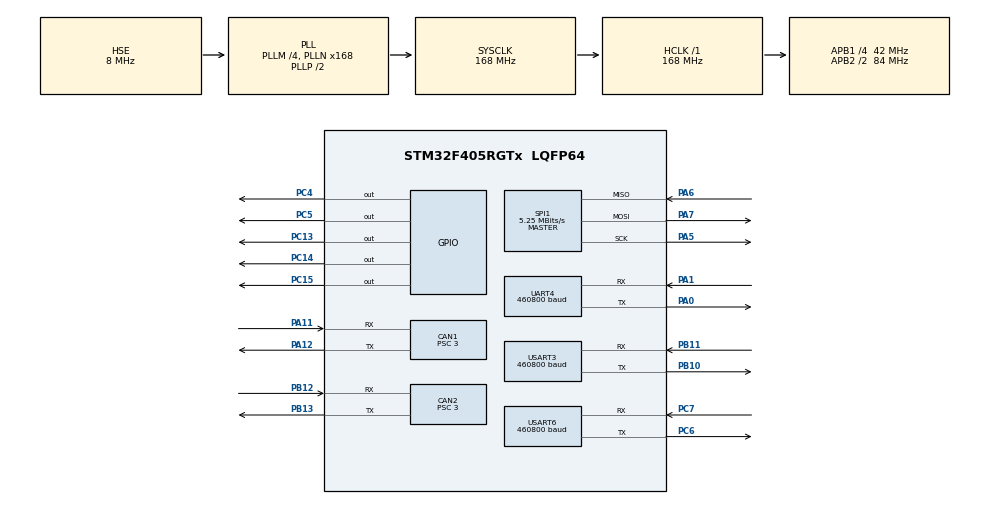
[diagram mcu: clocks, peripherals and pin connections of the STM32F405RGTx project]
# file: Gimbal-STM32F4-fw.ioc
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CAN1.BS1=CAN_BS1_9TQ
CAN1.BS2=CAN_BS2_4TQ
CAN1.CalculateBaudRate=1000000
CAN1.CalculateTimeBit=1000
CAN1.CalculateTimeQuantum=71.42857142857143
CAN1.Prescaler=3
CAN2.BS1=CAN_BS1_9TQ
CAN2.BS2=CAN_BS2_4TQ
CAN2.CalculateBaudRate=1000000
CAN2.CalculateTimeBit=1000
CAN2.CalculateTimeQuantum=71.42857142857143
CAN2.Prescaler=3
Dma.Request0=USART3_RX
Dma.Request1=USART3_TX
Dma.Request2=UART4_RX
Dma.Request3=UART4_TX
Dma.Request4=USART6_RX
Dma.Request5=USART6_TX
Dma.UART4_RX.2.Direction=DMA_PERIPH_TO_MEMORY
Dma.UART4_RX.2.FIFOMode=DMA_FIFOMODE_DISABLE
Dma.UART4_RX.2.Instance=DMA1_Stream2
Dma.UART4_RX.2.MemDataAlignment=DMA_MDATAALIGN_BYTE
Dma.UART4_RX.2.MemInc=DMA_MINC_ENABLE
Dma.UART4_RX.2.Mode=DMA_CIRCULAR
Dma.UART4_RX.2.PeriphDataAlignment=DMA_PDATAALIGN_BYTE
Dma.UART4_RX.2.PeriphInc=DMA_PINC_DISABLE
Dma.UART4_RX.2.Priority=DMA_PRIORITY_LOW
Dma.UART4_TX.3.Direction=DMA_MEMORY_TO_PERIPH
Dma.UART4_TX.3.FIFOMode=DMA_FIFOMODE_DISABLE
Dma.UART4_TX.3.Instance=DMA1_Stream4
Dma.UART4_TX.3.MemDataAlignment=DMA_MDATAALIGN_BYTE
Dma.UART4_TX.3.MemInc=DMA_MINC_ENABLE
Dma.UART4_TX.3.Mode=DMA_NORMAL
Dma.UART4_TX.3.PeriphDataAlignment=DMA_PDATAALIGN_BYTE
Dma.UART4_TX.3.PeriphInc=DMA_PINC_DISABLE
Dma.UART4_TX.3.Priority=DMA_PRIORITY_LOW
Dma.USART3_RX.0.Direction=DMA_PERIPH_TO_MEMORY
Dma.USART3_RX.0.FIFOMode=DMA_FIFOMODE_DISABLE
Dma.USART3_RX.0.Instance=DMA1_Stream1
Dma.USART3_RX.0.MemDataAlignment=DMA_MDATAALIGN_BYTE
Dma.USART3_RX.0.MemInc=DMA_MINC_ENABLE
Dma.USART3_RX.0.Mode=DMA_NORMAL
Dma.USART3_RX.0.PeriphDataAlignment=DMA_PDATAALIGN_BYTE
Dma.USART3_RX.0.PeriphInc=DMA_PINC_DISABLE
Dma.USART3_RX.0.Priority=DMA_PRIORITY_VERY_HIGH
Dma.USART3_TX.1.Direction=DMA_MEMORY_TO_PERIPH
Dma.USART3_TX.1.FIFOMode=DMA_FIFOMODE_DISABLE
Dma.USART3_TX.1.Instance=DMA1_Stream3
Dma.USART3_TX.1.MemDataAlignment=DMA_MDATAALIGN_BYTE
Dma.USART3_TX.1.MemInc=DMA_MINC_ENABLE
Dma.USART3_TX.1.Mode=DMA_NORMAL
Dma.USART3_TX.1.PeriphDataAlignment=DMA_PDATAALIGN_BYTE
Dma.USART3_TX.1.PeriphInc=DMA_PINC_DISABLE
Dma.USART3_TX.1.Priority=DMA_PRIORITY_VERY_HIGH
Dma.USART6_RX.4.Direction=DMA_PERIPH_TO_MEMORY
Dma.USART6_RX.4.FIFOMode=DMA_FIFOMODE_DISABLE
Dma.USART6_RX.4.Instance=DMA2_Stream1
Dma.USART6_RX.4.MemDataAlignment=DMA_MDATAALIGN_BYTE
Dma.USART6_RX.4.MemInc=DMA_MINC_ENABLE
Dma.USART6_RX.4.Mode=DMA_CIRCULAR
Dma.USART6_RX.4.PeriphDataAlignment=DMA_PDATAALIGN_BYTE
Dma.USART6_RX.4.PeriphInc=DMA_PINC_DISABLE
Dma.USART6_RX.4.Priority=DMA_PRIORITY_LOW
Dma.USART6_TX.5.Direction=DMA_MEMORY_TO_PERIPH
Dma.USART6_TX.5.FIFOMode=DMA_FIFOMODE_DISABLE
Dma.USART6_TX.5.Instance=DMA2_Stream6
Dma.USART6_TX.5.MemDataAlignment=DMA_MDATAALIGN_BYTE
Dma.USART6_TX.5.MemInc=DMA_MINC_ENABLE
Dma.USART6_TX.5.Mode=DMA_NORMAL
Dma.USART6_TX.5.PeriphDataAlignment=DMA_PDATAALIGN_BYTE
Dma.USART6_TX.5.PeriphInc=DMA_PINC_DISABLE
Dma.USART6_TX.5.Priority=DMA_PRIORITY_LOW
Mcu.Family=STM32F4
Mcu.Name=STM32F405RGTx
Mcu.Package=LQFP64
NVIC.CAN1_RX0_IRQn=true\:0\:0\:false\:false\:true\:true\:true\:true
NVIC.CAN2_RX0_IRQn=true\:0\:0\:false\:false\:true\:true\:true\:true
NVIC.DMA1_Stream1_IRQn=true\:0\:0\:false\:false\:true\:false\:true\:true
NVIC.DMA1_Stream2_IRQn=true\:0\:0\:false\:false\:true\:false\:true\:true
NVIC.DMA1_Stream3_IRQn=true\:0\:0\:false\:false\:true\:false\:true\:true
NVIC.DMA1_Stream4_IRQn=true\:0\:0\:false\:false\:true\:false\:true\:true
NVIC.DMA2_Stream1_IRQn=true\:0\:0\:false\:false\:true\:false\:true\:true
NVIC.DMA2_Stream6_IRQn=true\:0\:0\:false\:false\:true\:false\:true\:true
NVIC.PriorityGroup=NVIC_PRIORITYGROUP_4
NVIC.UART4_IRQn=true\:0\:0\:false\:false\:true\:true\:true\:true
NVIC.USART3_IRQn=true\:0\:0\:false\:false\:true\:true\:true\:true
NVIC.USART6_IRQn=true\:0\:0\:false\:false\:true\:true\:true\:true
PA0-WKUP.GPIO_ModeDefaultPP=GPIO_MODE_AF_OD
PA0-WKUP.GPIO_PuPd=GPIO_PULLUP
PA0-WKUP.Mode=Asynchronous
PA0-WKUP.Signal=UART4_TX
PA1.GPIO_ModeDefaultPP=GPIO_MODE_AF_OD
PA1.GPIO_PuPd=GPIO_PULLUP
PA1.Mode=Asynchronous
PA1.Signal=UART4_RX
PA11.GPIO_PuPd=GPIO_PULLUP
PA11.Mode=CAN_Activate
PA11.Signal=CAN1_RX
PA12.GPIO_PuPd=GPIO_PULLUP
PA12.Mode=CAN_Activate
PA12.Signal=CAN1_TX
PA13.Mode=Serial_Wire
PA13.Signal=SYS_JTMS-SWDIO
PA14.Mode=Serial_Wire
PA14.Signal=SYS_JTCK-SWCLK
PA5.GPIO_PuPd=GPIO_PULLUP
PA5.Mode=Full_Duplex_Master
PA5.Signal=SPI1_SCK
PA6.GPIO_PuPd=GPIO_PULLUP
PA6.Mode=Full_Duplex_Master
PA6.Signal=SPI1_MISO
PA7.GPIO_PuPd=GPIO_PULLUP
PA7.Mode=Full_Duplex_Master
PA7.Signal=SPI1_MOSI
PB10.GPIO_ModeDefaultPP=GPIO_MODE_AF_OD
PB10.GPIO_PuPd=GPIO_PULLUP
PB10.Mode=Asynchronous
PB10.Signal=USART3_TX
PB11.GPIO_ModeDefaultPP=GPIO_MODE_AF_OD
PB11.GPIO_PuPd=GPIO_PULLUP
PB11.Mode=Asynchronous
PB11.Signal=USART3_RX
PB12.GPIO_PuPd=GPIO_PULLUP
PB12.Mode=CAN_Activate
PB12.Signal=CAN2_RX
PB13.GPIO_PuPd=GPIO_PULLUP
PB13.Mode=CAN_Activate
PB13.Signal=CAN2_TX
PC13-ANTI_TAMP.GPIO_PuPd=GPIO_PULLUP
PC13-ANTI_TAMP.PinState=GPIO_PIN_RESET
PC13-ANTI_TAMP.Signal=GPIO_Output
PC14-OSC32_IN.GPIO_PuPd=GPIO_PULLUP
PC14-OSC32_IN.Signal=GPIO_Output
PC15-OSC32_OUT.GPIO_PuPd=GPIO_PULLUP
PC15-OSC32_OUT.Signal=GPIO_Output
PC4.GPIO_Speed=GPIO_SPEED_FREQ_HIGH
PC4.PinState=GPIO_PIN_SET
PC4.Signal=GPIO_Output
PC5.GPIO_Speed=GPIO_SPEED_FREQ_HIGH
PC5.PinState=GPIO_PIN_SET
PC5.Signal=GPIO_Output
PC6.Mode=Asynchronous
PC6.Signal=USART6_TX
PC7.Mode=Asynchronous
PC7.Signal=USART6_RX
PH0-OSC_IN.Mode=HSE-External-Oscillator
PH0-OSC_IN.Signal=RCC_OSC_IN
PH1-OSC_OUT.Mode=HSE-External-Oscillator
PH1-OSC_OUT.Signal=RCC_OSC_OUT
ProjectManager.HeapSize=0x200
ProjectManager.StackSize=0x400
ProjectManager.TargetToolchain=Makefile
RCC.48MHZClocksFreq_Value=84000000
RCC.AHBFreq_Value=168000000
RCC.APB1CLKDivider=RCC_HCLK_DIV4
RCC.APB1Freq_Value=42000000
RCC.APB1TimFreq_Value=84000000
RCC.APB2CLKDivider=RCC_HCLK_DIV2
RCC.APB2Freq_Value=84000000
RCC.APB2TimFreq_Value=168000000
RCC.CortexFreq_Value=168000000
RCC.HCLKFreq_Value=168000000
RCC.HSE_VALUE=8000000
RCC.HSI_VALUE=16000000
RCC.LSE_VALUE=32768
RCC.PLLM=4
RCC.PLLN=168
RCC.PLLSourceVirtual=RCC_PLLSOURCE_HSE
RCC.SYSCLKFreq_VALUE=168000000
RCC.SYSCLKSource=RCC_SYSCLKSOURCE_PLLCLK
RCC.VCOOutputFreq_Value=336000000
SPI1.BaudRatePrescaler=SPI_BAUDRATEPRESCALER_16
SPI1.CRCCalculation=SPI_CRCCALCULATION_DISABLE
SPI1.CalculateBaudRate=5.25 MBits/s
SPI1.DataSize=SPI_DATASIZE_8BIT
SPI1.Direction=SPI_DIRECTION_2LINES
SPI1.Mode=SPI_MODE_MASTER
SPI1.VirtualType=VM_MASTER
TIM5.AutoReloadPreload=TIM_AUTORELOAD_PRELOAD_ENABLE
TIM5.Prescaler=83
UART4.BaudRate=460800
UART4.VirtualMode=Asynchronous
USART3.BaudRate=460800
USART3.VirtualMode=VM_ASYNC
USART6.BaudRate=460800
USART6.VirtualMode=VM_ASYNC
VP_TIM5_VS_ClockSourceINT.Mode=Internal
board=custom

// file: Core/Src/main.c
/* USER CODE BEGIN Header */
/**
  ******************************************************************************
  * @file           : main.c
  * @brief          : Main program body
  ******************************************************************************
  * @attention
  *
  * Copyright (c) 2023 STMicroelectronics.
  * All rights reserved.
  *
  * This software is licensed under terms that can be found in the LICENSE file
  * in the root directory of this software component.
  * If no LICENSE file comes with this software, it is provided AS-IS.
  *
  ******************************************************************************
  */
/* USER CODE END Header */
#include "main.h"
#include "can.h"
#include "dma.h"
#include "spi.h"
#include "tim.h"
#include "usart.h"
#include "gpio.h"

/* USER CODE BEGIN Includes */
#include "user_main.h"
#include "retarget.h"
/* USER CODE END Includes */

void SystemClock_Config(void);

int main(void)
{

  /* MCU Configuration--------------------------------------------------------*/

  /* Reset of all peripherals, Initializes the Flash interface and the Systick. */
  HAL_Init();

  /* Configure the system clock */
  SystemClock_Config();

  /* Initialize all configured peripherals */
  MX_GPIO_Init();
  MX_DMA_Init();
  MX_CAN1_Init();
  MX_TIM5_Init();
  MX_USART3_UART_Init();
  MX_UART4_Init();
  MX_CAN2_Init();
  MX_SPI1_Init();
  MX_USART6_UART_Init();
  /* USER CODE BEGIN 2 */
  UserMain();
  /* USER CODE END 2 */

  /* Infinite loop */
  while (1)
  {

  }
}

void SystemClock_Config(void)
{
  RCC_OscInitTypeDef RCC_OscInitStruct = {0};
  RCC_ClkInitTypeDef RCC_ClkInitStruct = {0};

  /** Configure the main internal regulator output voltage
  */
  __HAL_RCC_PWR_CLK_ENABLE();
  __HAL_PWR_VOLTAGESCALING_CONFIG(PWR_REGULATOR_VOLTAGE_SCALE1);

  /** Initializes the RCC Oscillators according to the specified parameters
  * in the RCC_OscInitTypeDef structure.
  */
  RCC_OscInitStruct.OscillatorType = RCC_OSCILLATORTYPE_HSE;
  RCC_OscInitStruct.HSEState = RCC_HSE_ON;
  RCC_OscInitStruct.PLL.PLLState = RCC_PLL_ON;
  RCC_OscInitStruct.PLL.PLLSource = RCC_PLLSOURCE_HSE;
  RCC_OscInitStruct.PLL.PLLM = 4;
  RCC_OscInitStruct.PLL.PLLN = 168;
  RCC_OscInitStruct.PLL.PLLP = RCC_PLLP_DIV2;
  RCC_OscInitStruct.PLL.PLLQ = 4;
  if (HAL_RCC_OscConfig(&RCC_OscInitStruct) != HAL_OK)
  {
    Error_Handler();
  }

  /** Initializes the CPU, AHB and APB buses clocks
  */
  RCC_ClkInitStruct.ClockType = RCC_CLOCKTYPE_HCLK|RCC_CLOCKTYPE_SYSCLK
                              |RCC_CLOCKTYPE_PCLK1|RCC_CLOCKTYPE_PCLK2;
  RCC_ClkInitStruct.SYSCLKSource = RCC_SYSCLKSOURCE_PLLCLK;
  RCC_ClkInitStruct.AHBCLKDivider = RCC_SYSCLK_DIV1;
  RCC_ClkInitStruct.APB1CLKDivider = RCC_HCLK_DIV4;
  RCC_ClkInitStruct.APB2CLKDivider = RCC_HCLK_DIV2;

  if (HAL_RCC_ClockConfig(&RCC_ClkInitStruct, FLASH_LATENCY_5) != HAL_OK)
  {
    Error_Handler();
  }
}

void Error_Handler(void)
{
  __disable_irq();
  while (1)
  {
  }
}
